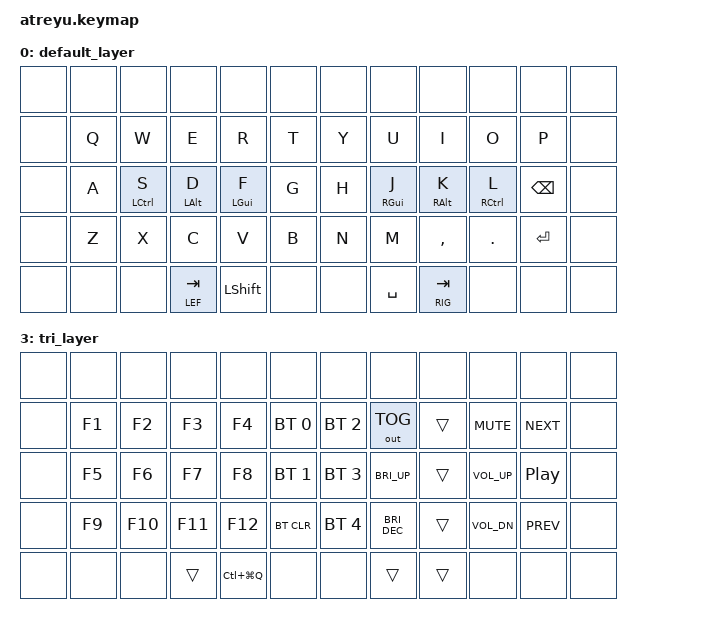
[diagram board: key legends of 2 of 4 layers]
// Copyright (c) 2022 The ZMK Contributors
// SPDX-License-Identifier: MIT

#include <behaviors.dtsi>
#include <dt-bindings/zmk/keys.h>
#include <dt-bindings/zmk/bt.h>
#include <dt-bindings/zmk/outputs.h>

// Home row mods macro
#define HRML(k2,k3,k4) &ht LCTRL k2  &ht LALT k3  &ht LGUI k4
#define HRMR(k1,k2,k3) &ht RGUI k1  &ht RALT k2  &ht RCTRK k3

#define MAC 0
#define RIG 1
#define LEF 2
#define TRI 3

/ {
    behaviors {
        ht: hold_tap {
            label = "hold_tap";
            compatible = "zmk,behavior-hold-tap";
            #binding-cells = <2>;
            flavor = "tap-preferred";
            tapping-term-ms = <220>;
            quick-tap-ms = <150>;
            global-quick-tap;
            bindings = <&kp>, <&kp>;
        };
	    ctrl_tab: ctrl_tab {
		compatible = "zmk,behavior-mod-morph";
		label = "GUI_CTRL_TAB";
		#binding-cells = <0>;
		bindings = <&kp LC(TAB)>, <&kp LC(LS(TAB))>;
		mods = <(MOD_LGUI)>;
	    };
	    shiftable_tab: shiftable_tab {
		compatible = "zmk,behavior-mod-morph";
		label = "CTRL_TAB";
		#binding-cells = <0>;
		bindings = <&kp TAB >, <&ctrl_tab>;
		mods = <(MOD_LCTL)>;
	    };
    };

    conditional_layers {
        compatible = "zmk,conditional-layers";
        tri_layer {
            if-layers = <RIG LEF>;
            then-layer = <TRI>;
        };
    };

    keymap {
        compatible = "zmk,keymap";
        default_layer {
            bindings = <
   &none  &none  &none  &none  &none  &none  &none  &none  &none  &none  &none  &none
        //╭──────────┬──────────┬──────────┬──────────┬──────────╮             ╭──────────┬──────────┬──────────┬──────────┬──────────╮
        //│  Q       │  W       │  E       │  R       │  T       │             │  Y       │  U       │  I       │  O       │  P       │
   &none    &kp Q      &kp W      &kp E      &kp R      &kp T                    &kp Y      &kp U      &kp I      &kp O      &kp P       &none
        //├──────────┼──────────┼──────────┼──────────┼──────────┤             ├──────────┼──────────┼──────────┼──────────┼──────────┤
        //│  A       │  S       │  D       │  F       │  G       │             │  H       │  J       │  K       │  L       │BACKSPACE │
   &none    &kp A    &ht LCTRL S &ht LALT D &ht LGUI F &kp G                    &kp H      &ht RGUI J &ht RALT K &ht RCTRL L &kp BSPC    &none
        //├──────────┼──────────┼──────────┼──────────┼──────────┤             ├──────────┼──────────┼──────────┼──────────┼──────────┤
        //│  Z       │  X       │  C       │  V       │  B       │             │  N       │  M       │ , <      │ . >      │ ENTER    │
   &none    &kp Z      &kp X      &kp C      &kp V      &kp B                    &kp N      &kp M      &kp COMMA  &kp DOT    &kp ENTER   &none
        //╰──────────┴──────────┴──────────┼──────────┼──────────┤             ├──────────┼──────────┼──────────┴──────────┴──────────╯
        //                                 │  TAB     │ SHIFT    │             │ SPACE    │  TAB     │ 
   &none &none &none                       &lt LEF TAB  &kp LSHIFT &none &none  &kp SPACE  &lt RIG TAB  &none &none &none
        //                                 ╰──────────┴──────────╯             ╰──────────┴──────────╯
            >;
        };

        right_layer {
            bindings = <
   &none  &none  &none  &none  &none  &none  &none  &none  &none  &none  &none  &none
        //╭──────────┬──────────┬──────────┬──────────┬──────────╮             ╭──────────┬──────────┬──────────┬──────────┬──────────╮
        //│ 1        │  2       │  3       │  4       │  5       │             │ 6        │ 7        │ 8        │ 9        │   0      │
   &none    &kp N1    &kp N2     &kp N3     &kp N4     &kp N5                    &kp N6     &kp N7     &kp N8     &kp N9      &kp N0    &none
        //├──────────┼──────────┼──────────┼──────────┼──────────┤             ├──────────┼──────────┼──────────┼──────────┼──────────┤
        //│ DELETE   │          │          │  INSERT  │  ESC     │             │ PAGE UP  │ HOME     │ UP       │ END      │          │
   &none    &kp DEL   &trans     &trans     &kp INS     &kp ESC                  &kp PG_UP  &kp HOME   &kp UARW   &kp END    &trans     &none
        //├──────────┼──────────┼──────────┼──────────┼──────────┤             ├──────────┼──────────┼──────────┼──────────┼──────────┤
        //│          │          │          │          │  ESC     │             │ PAGE DN  │ LEFT     │ DOWN     │ RIGHT    │          │
   &none    &trans    &trans     &trans     &trans      &kp ESC                  &kp PG_DN  &kp LARW   &kp DARW   &kp RARW   &trans   &none
        //╰──────────┴──────────┴──────────┼──────────┼──────────┤             ├──────────┼──────────┼──────────┴──────────┴──────────╯
        //                                 │          │          │             │          │          │ 
   &none &none &none                         &trans     &trans    &none &none    &trans     &trans
        //                                 ╰──────────┴──────────╯             ╰──────────┴──────────╯
            >;
        };

        left_layer {
            bindings = <
   &none  &none  &none  &none  &none  &none  &none  &none  &none  &none  &none  &none
        //╭──────────┬──────────┬──────────┬──────────┬──────────╮             ╭──────────┬──────────┬──────────┬──────────┬──────────╮
        //│  !       │  @       │  #       │  $       │  %       │             │  ^       │  &       │  *       │  `       │  ~       │
   &none    &kp EXCL   &kp AT     &kp HASH   &kp DLLR   &kp PRCNT                &kp CARET  &kp AMPS   &kp ASTRK  &kp GRAVE   &kp TILDE &none
        //├──────────┼──────────┼──────────┼──────────┼──────────┤             ├──────────┼──────────┼──────────┼──────────┼──────────┤
        //│  "       │  [       │  {       │  (       │  ESC     │             │  /       │  -       │  =       │  :       │  ;       │
   &none    &kp DQT    &kp LBKT   &kp LBRC   &kp LPAR   &kp ESC                  &kp FSLH   &kp MINUS  &kp EQUAL  &kp COLON   &kp SEMI &none
        //├──────────┼──────────┼──────────┼──────────┼──────────┤             ├──────────┼──────────┼──────────┼──────────┼──────────┤
        //│  '       │  ]       │  }       │  )       │  ESC     │             │  \       │  _       │  +       │  │       │  ?       │
   &none    &kp SQT    &kp RBKT   &kp RBRC   &kp RPAR   &kp ESC                  &kp BSLH   &kp UNDER  &kp PLUS   &kp PIPE  &kp QMARK &none
        //╰──────────┴──────────┴──────────┼──────────┼──────────┤             ├──────────┼──────────┼──────────┴──────────┴──────────╯
        //                                 │          │          │             │          │          │ 
   &none &none &none                         &trans     &trans     &none &none   &trans     &trans
        //                                 ╰──────────┴──────────╯             ╰──────────┴──────────╯
            >;
        };

        tri_layer {
            bindings = <
   &none  &none  &none  &none  &none  &none  &none  &none  &none  &none  &none  &none
        //╭──────────┬──────────┬──────────┬───────────┬────────────╮             ╭────────────┬────────────┬──────────┬───────────┬──────────╮
        //│  F1      │  F2      │  F3      │  F4       │ PROFILE 0  │             │ PROFILE 2  │ TOGGLEOUT  │ WINDOWS  │ VOL MUTE  │ NEXTSONG │
   &none    &kp F1     &kp F2     &kp F3     &kp F4     &bt BT_SEL 0               &bt BT_SEL 2  &out OUT_TOG &trans    &kp C_MUTE  &kp C_NEXT &none
        //├──────────┼──────────┼──────────┼───────────┼────────────┤             ├────────────┼────────────┼──────────┼───────────┼──────────┤
        //│  F5      │  F6      │  F7      │  F8       │ PROFILE 1  │             │ PROFILE 3  │ INC BRIGHT │          │  VOL UP   │PAUSEMUSIC│
   &none    &kp F5     &kp F6     &kp F7     &kp F8     &bt BT_SEL 1               &bt BT_SEL 3  &kp C_BRI_UP  &trans   &kp C_VOL_UP  &kp C_PP &none
        //├──────────┼──────────┼──────────┼───────────┼────────────┤             ├────────────┼────────────┼──────────┼───────────┼──────────┤
        //│  F9      │  F10     │  F11     │  F12      │  CLEAR BT  │             │ PROFILE 4  │ DEC BRIGHT │          │  VOL DOWN │ PREVSONG │
   &none    &kp F9     &kp F10    &kp F11    &kp F12     &bt BT_CLR                &bt BT_SEL 4  &kp C_BRI_DEC  &trans   &kp C_VOL_DN &kp C_PREV &none
        //╰──────────┴──────────┴──────────┼───────────┼────────────┤             ├────────────┼────────────┼──────────┴───────────┴──────────╯
        //                                 │           │            │             │            │            │ 
   &none &none &none                            &trans  &kp LC(LG(Q)) &none &none  &trans       &trans       &none &none &none 
        //                                 ╰───────────┴────────────╯             ╰────────────┴────────────╯
            >;
        };
    };
};

        //╭──────────┬──────────┬──────────┬──────────┬──────────╮             ╭──────────┬──────────┬──────────┬──────────┬──────────╮
        //│  Q       │  W       │  E       │  R       │  T       │             │  Y       │  U       │  I       │  O       │  P       │
        //├──────────┼──────────┼──────────┼──────────┼──────────┤             ├──────────┼──────────┼──────────┼──────────┼──────────┤
        //│  A       │  S       │  D       │  F       │  G       │             │  H       │  J       │  K       │  L       │BACKSPACE │
        //├──────────┼──────────┼──────────┼──────────┼──────────┤             ├──────────┼──────────┼──────────┼──────────┼──────────┤
        //│  Z       │  X       │  C       │  V       │  B       │             │  N       │  M       │ , <      │ . >      │ ENTER    │
        //╰──────────┴──────────┴──────────┼──────────┼──────────┤             ├──────────┼──────────┼──────────┴──────────┴──────────╯
        //                                 │  TAB     │ SHIFT    │             │ SPACE    │  TAB     │ 
        //                                 ╰──────────┴──────────╯             ╰──────────┴──────────╯
        //╭──────────┬──────────┬──────────┬──────────┬──────────╮             ╭──────────┬──────────┬──────────┬──────────┬──────────╮
        //│ 1        │  2       │  3       │  4       │  5       │             │ 6        │ 7        │ 8        │ 9        │   0      │
        //├──────────┼──────────┼──────────┼──────────┼──────────┤             ├──────────┼──────────┼──────────┼──────────┼──────────┤
        //│ DELETE   │          │          │  INSERT  │          │             │ PAGE UP  │ HOME     │ UP       │ END      │          │
        //├──────────┼──────────┼──────────┼──────────┼──────────┤             ├──────────┼──────────┼──────────┼──────────┼──────────┤
        //│          │          │          │          │          │             │ PAGE DN  │ LEFT     │ DOWN     │ RIGHT    │          │
        //╰──────────┴──────────┴──────────┼──────────┼──────────┤             ├──────────┼──────────┼──────────┴──────────┴──────────╯
        //                                 │          │  ESC     │             │          │          │ 
        //                                 ╰──────────┴──────────╯             ╰──────────┴──────────╯
        //╭──────────┬──────────┬──────────┬──────────┬──────────╮             ╭──────────┬──────────┬──────────┬──────────┬──────────╮
        //│  !       │  @       │  #       │  $       │  %       │             │  ^       │  &       │  *       │  `       │  ~       │
        //├──────────┼──────────┼──────────┼──────────┼──────────┤             ├──────────┼──────────┼──────────┼──────────┼──────────┤
        //│  "       │  [       │  {       │  (       │          │             │  /       │  -       │  =       │  :       │  ;       │
        //├──────────┼──────────┼──────────┼──────────┼──────────┤             ├──────────┼──────────┼──────────┼──────────┼──────────┤
        //│  '       │  ]       │  }       │  )       │          │             │  \       │  _       │  +       │  │       │  ?       │
        //╰──────────┴──────────┴──────────┼──────────┼──────────┤             ├──────────┼──────────┼──────────┴──────────┴──────────╯
        //                                 │          │          │             │          │          │ 
        //                                 ╰──────────┴──────────╯             ╰──────────┴──────────╯
        //╭──────────┬──────────┬──────────┬───────────┬────────────╮             ╭────────────┬────────────┬──────────┬───────────┬──────────╮
        //│  F1      │  F2      │  F3      │  F4       │ PROFILE 0  │             │ PROFILE 2  │ TOGGLEOUT  │          │ VOL MUTE  │ NEXTSONG │
        //├──────────┼──────────┼──────────┼───────────┼────────────┤             ├────────────┼────────────┼──────────┼───────────┼──────────┤
        //│  F5      │  F6      │  F7      │  F8       │ PROFILE 1  │             │ PROFILE 3  │ INC BRIGHT │          │  VOL UP   │PAUSEMUSIC│
        //├──────────┼──────────┼──────────┼───────────┼────────────┤             ├────────────┼────────────┼──────────┼───────────┼──────────┤
        //│  F9      │  F10     │  F11     │  F12      │  CLEAR BT  │             │ PROFILE 4  │ DEC BRIGHT │          │  VOL DOWN │ PREVSONG │
        //╰──────────┴──────────┴──────────┼───────────┼────────────┤             ├────────────┼────────────┼──────────┴───────────┴──────────╯
        //                                 │           │            │             │            │            │ 
        //                                 ╰───────────┴────────────╯             ╰────────────┴────────────╯
	
